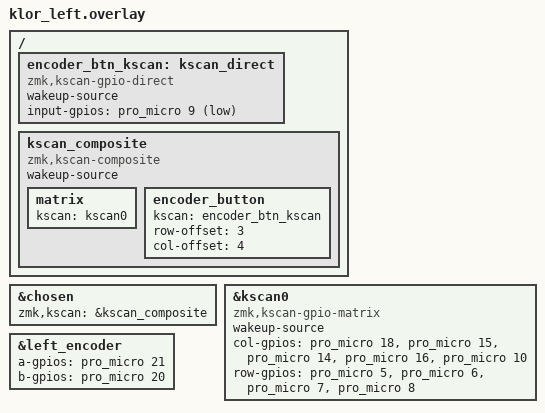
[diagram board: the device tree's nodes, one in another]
/*
 * Copyright (c) 2022 GEIST
 *
 * SPDX-License-Identifier: MIT
 *
 */
#include "klor.dtsi"

// 1. Tell the keyboard matrix to use our combined layout rather than the stock one
&chosen {
    zmk,kscan = &kscan_composite;
};

// 2. Track your standard matrix rows and columns normally
&kscan0 {
    compatible = "zmk,kscan-gpio-matrix";
    wakeup-source;
    col-gpios
        = <&pro_micro 18 GPIO_ACTIVE_HIGH>
        , <&pro_micro 15 GPIO_ACTIVE_HIGH>
        , <&pro_micro 14 GPIO_ACTIVE_HIGH>
        , <&pro_micro 16 GPIO_ACTIVE_HIGH>
        , <&pro_micro 10 GPIO_ACTIVE_HIGH>
        ;
    row-gpios
        = <&pro_micro 5 (GPIO_ACTIVE_HIGH | GPIO_PULL_DOWN)>
        , <&pro_micro 6 (GPIO_ACTIVE_HIGH | GPIO_PULL_DOWN)>
        , <&pro_micro 7 (GPIO_ACTIVE_HIGH | GPIO_PULL_DOWN)>
        , <&pro_micro 8 (GPIO_ACTIVE_HIGH | GPIO_PULL_DOWN)>
        ;
};

&left_encoder {
    a-gpios = <&pro_micro 21 (GPIO_ACTIVE_HIGH | GPIO_PULL_UP)>;
    b-gpios = <&pro_micro 20 (GPIO_ACTIVE_HIGH | GPIO_PULL_UP)>;
    status = "okay";
};

// 3. Create the composite drivers to inject the hardware button safely
/ {
    // Listen directly to Pro Micro Pin 9 for the encoder click
    encoder_btn_kscan: kscan_direct {
        compatible = "zmk,kscan-gpio-direct";
        wakeup-source;
        input-gpios
            = <&pro_micro 9 (GPIO_ACTIVE_LOW | GPIO_PULL_UP)>;
    };

    // Combine your 36 keys with this 1 extra hardware button
    kscan_composite: kscan_composite {
        compatible = "zmk,kscan-composite";
        wakeup-source;
        #size-cells = <0>;

        // Standard Matrix (Rows 0-3, Columns 0-9)
        matrix {
            kscan = <&kscan0>;
        };

        // Encoder button appended as an extra matrix position
        encoder_button {
            kscan = <&encoder_btn_kscan>;
            row-offset = <3>; // Maps safely to an abstract matrix slot
            col-offset = <4>; 
        };
    };
};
